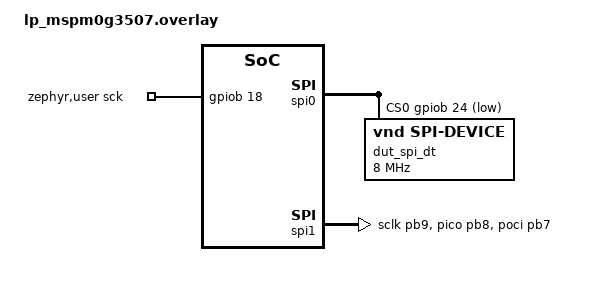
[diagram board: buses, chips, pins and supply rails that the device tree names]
/*
 * SPDX-FileCopyrightText: Copyright (c) 2026 Linumiz
 *
 * SPDX-License-Identifier: Apache-2.0
 */
/ {
	zephyr,user {
		sck-gpios = <&gpiob 18 GPIO_ACTIVE_HIGH>;
	};
};

&spi0 {
	cs-gpios = <&gpiob 24 GPIO_ACTIVE_LOW>;
	interrupts = <9 1>;
	status = "okay";

	dut_spi_dt: test-spi-dev@0 {
		compatible = "vnd,spi-device";
		reg = <0>;
		spi-max-frequency = <8000000>;
	};
};

dut_spis: &spi1 {
	pinctrl-0 = <&spi1_sclk_pb9 &spi1_pico_pb8 &spi1_poci_pb7>;
	pinctrl-1 = <&spi1_cs0_pb6>;
	pinctrl-names = "default", "hw_cs";
	interrupts = <10 0>;
	status = "okay";
};
